VERSION ""

NS_ :

BS_:
BU_: Gearbox
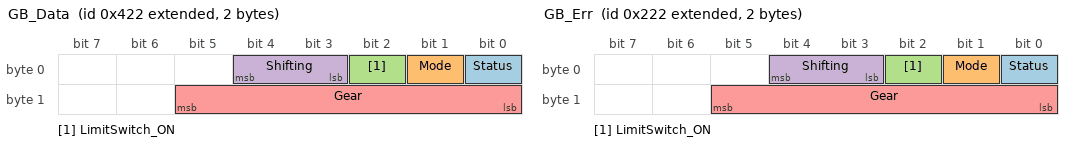
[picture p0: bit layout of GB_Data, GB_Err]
BO_ 2147484706 GB_Data: 2 Gearbox
   SG_ Status : 0|1@1+ (1,0) [0|1] "" Vector__XXX
   SG_ Mode : 1|1@1+ (1,0) [0|1] "" Vector__XXX
   SG_ LimitSwitch_ON : 2|1@1+ (1,0) [0|1] "" Vector__XXX
   SG_ Shifting : 3|2@1+ (1,0) [0|3] "" Vector__XXX
   SG_ Gear : 8|6@1+ (1,0) [0|15] "" Vector__XXX

BO_ 2147484194 GB_Err: 2 Gearbox
   SG_ Status : 0|1@0+ (1,0) [0|1] "" Vector__XXX
   SG_ Mode : 1|1@1+ (1,0) [0|1] "" Vector__XXX
   SG_ LimitSwitch_ON : 2|1@1+ (1,0) [0|1] "" Vector__XXX
   SG_ Shifting : 3|2@1+ (1,0) [0|3] "" Vector__XXX
   SG_ Gear : 8|6@1+ (1,0) [0|15] "" Vector__XXX

CM_ BU_ Gearbox "Gearbox CAN node";
CM_ BO_ 2147484706 "Gearbox Data";
CM_ SG_ 2147484706 Status "Status_of_the_gearbox_(working/error)";
CM_ SG_ 2147484706 Mode "Mode_of_the_gearbox_(gearbox/calibration)";
CM_ SG_ 2147484706 LimitSwitch_ON "Status_of_the_limit_switch_(on/off)";
CM_ SG_ 2147484706 Shifting "Shifting_(up/down)_or_not";
CM_ SG_ 2147484706 Gear "Current_Gear";
CM_ BO_ 2147484194 "Gearbox Error";
CM_ SG_ 2147484194 Status "Status_of_the_gearbox_(working/error)";
CM_ SG_ 2147484194 Mode "Mode_of_the_gearbox_(gearbox/calibration)";
CM_ SG_ 2147484194 LimitSwitch_ON "Status_of_the_limit_switch_(on/off)";
CM_ SG_ 2147484194 Shifting "Shifting_(up/down)_or_not";
CM_ SG_ 2147484194 Gear "Current_Gear";
BA_DEF_ BO_ "GenMsgBackgroundColor" STRING ;
BA_DEF_ BO_ "GenMsgForegroundColor" STRING ;
BA_DEF_ BO_ "filterlabeling" INT 0 0;
BA_DEF_ BO_ "filterlabeling" INT 0 0;
BA_DEF_ BO_ "filterlabeling" INT 0 0;
BA_DEF_DEF_ "GenMsgBackgroundColor" "#ffffff";
BA_DEF_DEF_ "GenMsgForegroundColor" "#000000";
BA_DEF_DEF_ "filterlabeling" 1;
BA_DEF_DEF_ "filterlabeling" 1;
